# AUX_SCE register map
Vendor: Texas Instruments
Peripheral module from a debugger description file (folder CC26x0R2F).
Registers are 32-bit, read-only, reset 0x0 unless marked. A register's access mark holds for its fields unless they carry their own. Offsets are as the file gives them; lines under a group give offsets from that group; [hi:lo] are bit positions; {n}, {i} and the like mark numbered series; 'fields as' and 'values as' point back to an identical list; <NAME> marks a mode.

## AUX_SCE — AUX Sensor Control Engine Control Module
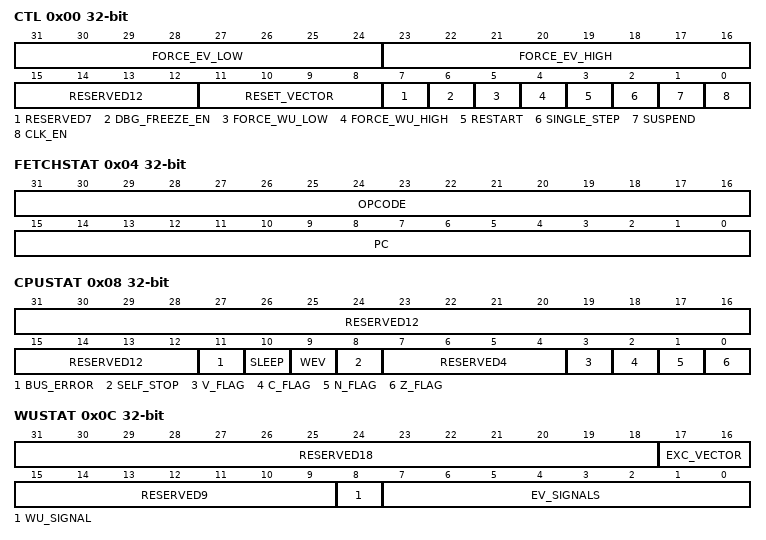
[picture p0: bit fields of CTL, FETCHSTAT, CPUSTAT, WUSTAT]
0x00 CTL access per field — Internal. Only to be used through TI provided API.
  [31:24] FORCE_EV_LOW rw — Internal. Only to be used through TI provided API.
  [23:16] FORCE_EV_HIGH rw — Internal. Only to be used through TI provided API.
  [15:12] RESERVED12 ro — Internal. Only to be used through TI provided API.
  [11:8] RESET_VECTOR rw — Internal. Only to be used through TI provided API.
  [7] RESERVED7 ro — Internal. Only to be used through TI provided API.
  [6] DBG_FREEZE_EN wo — Internal. Only to be used through TI provided API.
  [5] FORCE_WU_LOW rw — Internal. Only to be used through TI provided API.
  [4] FORCE_WU_HIGH rw — Internal. Only to be used through TI provided API.
  [3] RESTART rw — Internal. Only to be used through TI provided API.
  [2] SINGLE_STEP rw — Internal. Only to be used through TI provided API.
  [1] SUSPEND rw — Internal. Only to be used through TI provided API.
  [0] CLK_EN rw — Internal. Only to be used through TI provided API.
0x04 FETCHSTAT — Internal. Only to be used through TI provided API.
  [31:16] OPCODE — Internal. Only to be used through TI provided API.
  [15:0] PC — Internal. Only to be used through TI provided API.
0x08 CPUSTAT — Internal. Only to be used through TI provided API.
  [31:12] RESERVED12 — Internal. Only to be used through TI provided API.
  [11] BUS_ERROR — Internal. Only to be used through TI provided API.
  [10] SLEEP — Internal. Only to be used through TI provided API.
  [9] WEV — Internal. Only to be used through TI provided API.
  [8] SELF_STOP — Internal. Only to be used through TI provided API.
  [7:4] RESERVED4 — Internal. Only to be used through TI provided API.
  [3] V_FLAG — Internal. Only to be used through TI provided API.
  [2] C_FLAG — Internal. Only to be used through TI provided API.
  [1] N_FLAG — Internal. Only to be used through TI provided API.
  [0] Z_FLAG — Internal. Only to be used through TI provided API.
0x0C WUSTAT — Internal. Only to be used through TI provided API.
  [31:18] RESERVED18 — Internal. Only to be used through TI provided API.
  [17:16] EXC_VECTOR — Internal. Only to be used through TI provided API.
  [15:9] RESERVED9 — Internal. Only to be used through TI provided API.
  [8] WU_SIGNAL — Internal. Only to be used through TI provided API.
  [7:0] EV_SIGNALS — Internal. Only to be used through TI provided API.
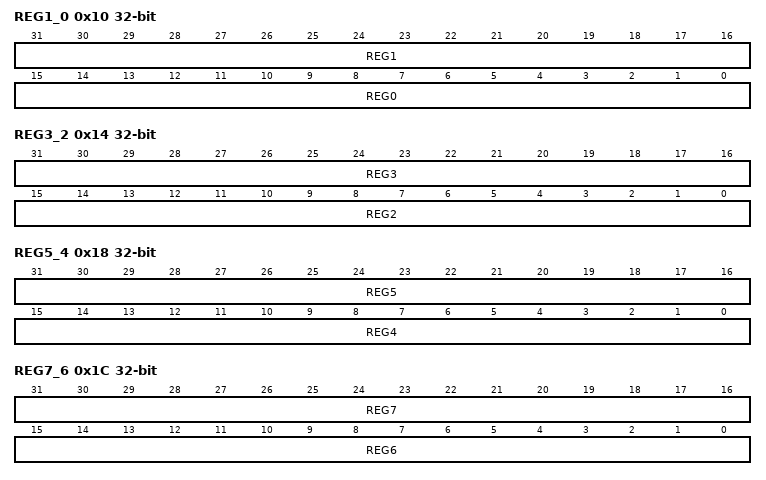
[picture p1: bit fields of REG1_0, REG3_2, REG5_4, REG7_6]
0x10 REG1_0 — Internal. Only to be used through TI provided API.
  [31:16] REG1 — Internal. Only to be used through TI provided API.
  [15:0] REG0 — Internal. Only to be used through TI provided API.
0x14 REG3_2 — Internal. Only to be used through TI provided API.
  [31:16] REG3 — Internal. Only to be used through TI provided API.
  [15:0] REG2 — Internal. Only to be used through TI provided API.
0x18 REG5_4 — Internal. Only to be used through TI provided API.
  [31:16] REG5 — Internal. Only to be used through TI provided API.
  [15:0] REG4 — Internal. Only to be used through TI provided API.
0x1C REG7_6 — Internal. Only to be used through TI provided API.
  [31:16] REG7 — Internal. Only to be used through TI provided API.
  [15:0] REG6 — Internal. Only to be used through TI provided API.
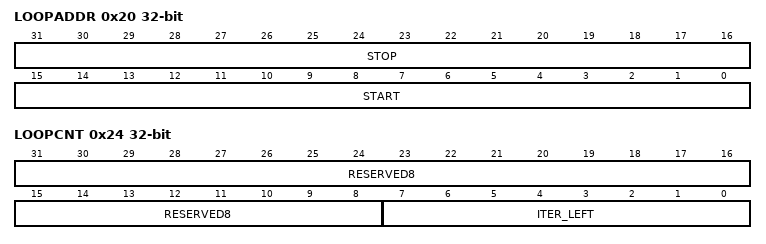
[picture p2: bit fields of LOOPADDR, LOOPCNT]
0x20 LOOPADDR — Internal. Only to be used through TI provided API.
  [31:16] STOP — Internal. Only to be used through TI provided API.
  [15:0] START — Internal. Only to be used through TI provided API.
0x24 LOOPCNT — Internal. Only to be used through TI provided API.
  [31:8] RESERVED8 — Internal. Only to be used through TI provided API.
  [7:0] ITER_LEFT — Internal. Only to be used through TI provided API.
